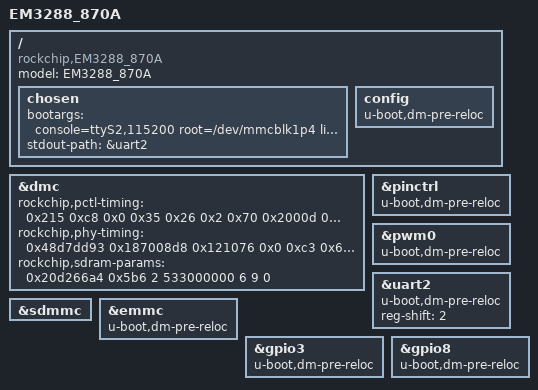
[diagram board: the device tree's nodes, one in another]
/*
 * (C) Copyright 2018 Yeacreate Co., Ltd
 *
 * SPDX-License-Identifier:     GPL-2.0+ X11
 */

/dts-v1/;
#include "EM3288_870A.dtsi"

/ {
	model = "EM3288_870A";
	compatible = "rockchip,EM3288_870A", "rockchip,rk3288";

	chosen {
		bootargs = "console=ttyS2,115200 root=/dev/mmcblk1p4 linuxroot rw rootfstype=ext4 init=/sbin/init fbcon=rotate:0 fb0=rotate:1";
		stdout-path = &uart2;
	};
	config {
		u-boot,dm-pre-reloc;
	};
};

&dmc {
	rockchip,pctl-timing = <0x215 0xc8 0x0 0x35 0x26 0x2 0x70 0x2000d
		0x6 0x0 0x8 0x4 0x17 0x24 0xd 0x6
		0x4 0x8 0x4 0x76 0x4 0x0 0x30 0x0
		0x1 0x2 0x2 0x4 0x0 0x0 0xc0 0x4
		0x8 0x1f4>;
		
	rockchip,phy-timing = <0x48d7dd93 0x187008d8 0x121076
		0x0 0xc3 0x6 0x2>;
	rockchip,sdram-params = <0x20d266a4 0x5b6 2 533000000 6 9 0>;
};

&pinctrl {
	u-boot,dm-pre-reloc;
	
};

&pwm0 {
	status = "okay";
	u-boot,dm-pre-reloc;
};

&uart2 {
	u-boot,dm-pre-reloc;
	reg-shift = <2>;
};

&sdmmc {
	//u-boot,dm-pre-reloc;
};

&emmc {
	u-boot,dm-pre-reloc;
};

&gpio3 {
	u-boot,dm-pre-reloc;
};

&gpio8 {
	u-boot,dm-pre-reloc;
};
